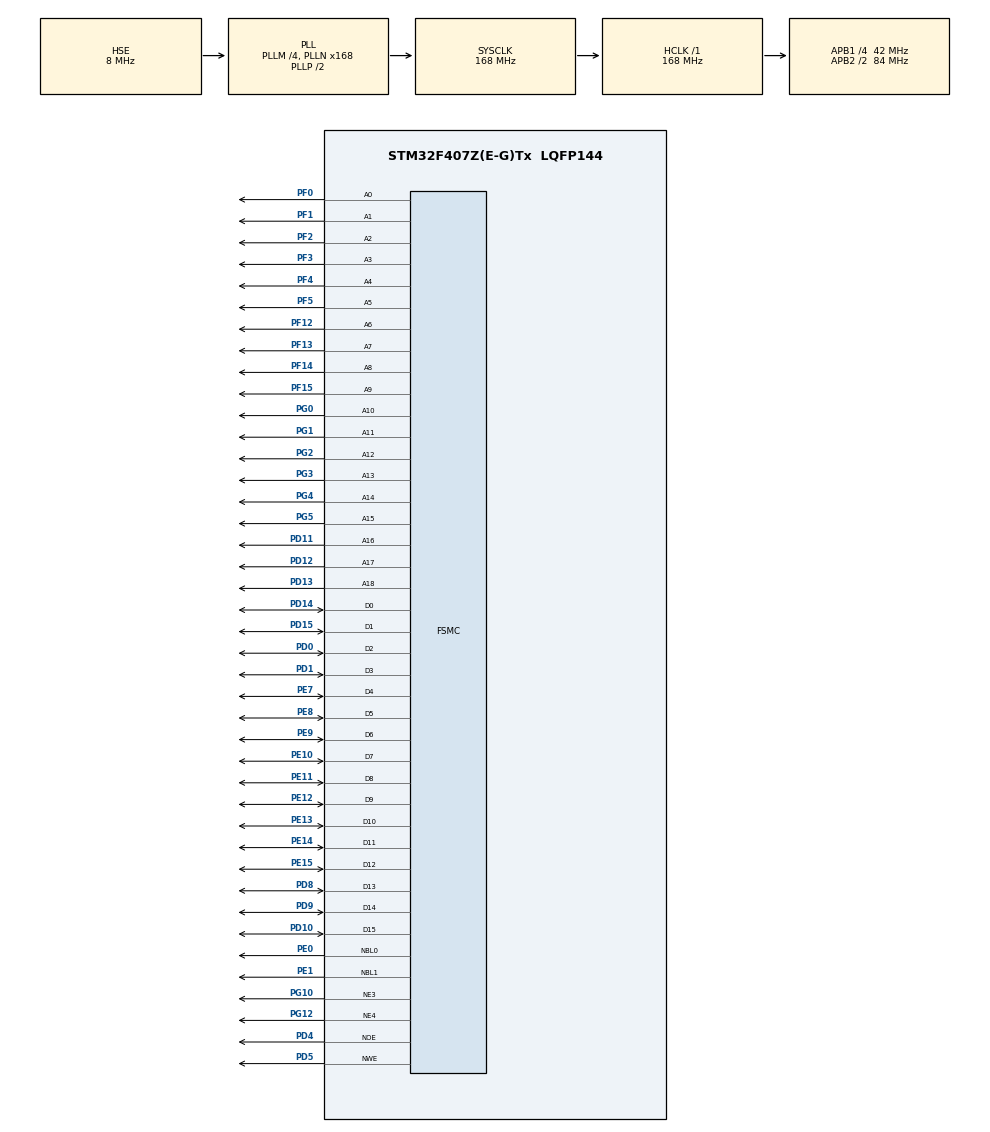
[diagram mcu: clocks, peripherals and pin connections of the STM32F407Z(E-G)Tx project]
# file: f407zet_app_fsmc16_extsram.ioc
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FSMC.AddressSetupTime1=3
FSMC.AddressSetupTime2=4
FSMC.BusTurnAroundDuration1=1
FSMC.BusTurnAroundDuration2=4
FSMC.DataSetupTime1=5
FSMC.DataSetupTime2=8
FSMC.WriteOperation1=FSMC_WRITE_OPERATION_ENABLE
Mcu.Family=STM32F4
Mcu.Name=STM32F407Z(E-G)Tx
Mcu.Package=LQFP144
NVIC.PriorityGroup=NVIC_PRIORITYGROUP_4
NVIC.TIM6_DAC_IRQn=true\:0\:0\:false\:false\:true\:false
NVIC.TimeBase=TIM6_DAC_IRQn
NVIC.TimeBaseIP=TIM6
PA13.Mode=Trace_Asynchronous_SW
PA13.Signal=SYS_JTMS-SWDIO
PA14.Mode=Trace_Asynchronous_SW
PA14.Signal=SYS_JTCK-SWCLK
PB3.Mode=Trace_Asynchronous_SW
PB3.Signal=SYS_JTDO-SWO
PC14-OSC32_IN.Mode=LSE-External-Oscillator
PC14-OSC32_IN.Signal=RCC_OSC32_IN
PC15-OSC32_OUT.Mode=LSE-External-Oscillator
PC15-OSC32_OUT.Signal=RCC_OSC32_OUT
PD0.Signal=FSMC_D2_DA2
PD1.Signal=FSMC_D3_DA3
PD10.Signal=FSMC_D15_DA15
PD11.Signal=FSMC_A16_CLE
PD12.Signal=FSMC_A17_ALE
PD13.Signal=FSMC_A18
PD14.Signal=FSMC_D0_DA0
PD15.Signal=FSMC_D1_DA1
PD4.Signal=FSMC_NOE
PD5.Signal=FSMC_NWE
PD8.Signal=FSMC_D13_DA13
PD9.Signal=FSMC_D14_DA14
PE0.Signal=FSMC_NBL0
PE1.Signal=FSMC_NBL1
PE10.Signal=FSMC_D7_DA7
PE11.Signal=FSMC_D8_DA8
PE12.Signal=FSMC_D9_DA9
PE13.Signal=FSMC_D10_DA10
PE14.Signal=FSMC_D11_DA11
PE15.Signal=FSMC_D12_DA12
PE7.Signal=FSMC_D4_DA4
PE8.Signal=FSMC_D5_DA5
PE9.Signal=FSMC_D6_DA6
PF0.Signal=FSMC_A0
PF1.Signal=FSMC_A1
PF12.Signal=FSMC_A6
PF13.Signal=FSMC_A7
PF14.Signal=FSMC_A8
PF15.Signal=FSMC_A9
PF2.Signal=FSMC_A2
PF3.Signal=FSMC_A3
PF4.Signal=FSMC_A4
PF5.Signal=FSMC_A5
PG0.Signal=FSMC_A10
PG1.Signal=FSMC_A11
PG10.Mode=NorPsramChipSelect3_1
PG10.Signal=FSMC_NE3
PG12.Mode=NorPsramChipSelect4_2
PG12.Signal=FSMC_NE4
PG2.Signal=FSMC_A12
PG3.Signal=FSMC_A13
PG4.Signal=FSMC_A14
PG5.Signal=FSMC_A15
PH0-OSC_IN.Mode=HSE-External-Oscillator
PH0-OSC_IN.Signal=RCC_OSC_IN
PH1-OSC_OUT.Mode=HSE-External-Oscillator
PH1-OSC_OUT.Signal=RCC_OSC_OUT
ProjectManager.HeapSize=0x200
ProjectManager.StackSize=0x800
ProjectManager.TargetToolchain=TrueSTUDIO
RCC.48MHZClocksFreq_Value=48000000
RCC.AHBFreq_Value=168000000
RCC.APB1CLKDivider=RCC_HCLK_DIV4
RCC.APB1Freq_Value=42000000
RCC.APB1TimFreq_Value=84000000
RCC.APB2CLKDivider=RCC_HCLK_DIV2
RCC.APB2Freq_Value=84000000
RCC.APB2TimFreq_Value=168000000
RCC.CortexFreq_Value=168000000
RCC.HCLKFreq_Value=168000000
RCC.HSE_VALUE=8000000
RCC.HSI_VALUE=16000000
RCC.PLLM=4
RCC.PLLN=168
RCC.PLLQ=7
RCC.PLLSourceVirtual=RCC_PLLSOURCE_HSE
RCC.RCC_RTC_Clock_Source=RCC_RTCCLKSOURCE_LSE
RCC.RCC_RTC_Clock_SourceVirtual=RCC_RTCCLKSOURCE_LSE
RCC.SYSCLKFreq_VALUE=168000000
RCC.SYSCLKSource=RCC_SYSCLKSOURCE_PLLCLK
RCC.VCOOutputFreq_Value=336000000
SH.FSMC_A0.0=FSMC_A0,19b-a1
SH.FSMC_A1.0=FSMC_A1,19b-a1
SH.FSMC_A10.0=FSMC_A10,19b-a1
SH.FSMC_A11.0=FSMC_A11,19b-a1
SH.FSMC_A12.0=FSMC_A12,19b-a1
SH.FSMC_A13.0=FSMC_A13,19b-a1
SH.FSMC_A14.0=FSMC_A14,19b-a1
SH.FSMC_A15.0=FSMC_A15,19b-a1
SH.FSMC_A16_CLE.0=FSMC_A16,19b-a1
SH.FSMC_A17_ALE.0=FSMC_A17,19b-a1
SH.FSMC_A18.0=FSMC_A18,19b-a1
SH.FSMC_A2.0=FSMC_A2,19b-a1
SH.FSMC_A3.0=FSMC_A3,19b-a1
SH.FSMC_A4.0=FSMC_A4,19b-a1
SH.FSMC_A5.0=FSMC_A5,19b-a1
SH.FSMC_A6.0=FSMC_A6,A6_2
SH.FSMC_A6.1=FSMC_A6,19b-a1
SH.FSMC_A7.0=FSMC_A7,19b-a1
SH.FSMC_A8.0=FSMC_A8,19b-a1
SH.FSMC_A9.0=FSMC_A9,19b-a1
SH.FSMC_D0_DA0.0=FSMC_D0,16b-d1
SH.FSMC_D0_DA0.1=FSMC_D0,16b-d2
SH.FSMC_D10_DA10.0=FSMC_D10,16b-d1
SH.FSMC_D10_DA10.1=FSMC_D10,16b-d2
SH.FSMC_D11_DA11.0=FSMC_D11,16b-d1
SH.FSMC_D11_DA11.1=FSMC_D11,16b-d2
SH.FSMC_D12_DA12.0=FSMC_D12,16b-d1
SH.FSMC_D12_DA12.1=FSMC_D12,16b-d2
SH.FSMC_D13_DA13.0=FSMC_D13,16b-d1
SH.FSMC_D13_DA13.1=FSMC_D13,16b-d2
SH.FSMC_D14_DA14.0=FSMC_D14,16b-d1
SH.FSMC_D14_DA14.1=FSMC_D14,16b-d2
SH.FSMC_D15_DA15.0=FSMC_D15,16b-d1
SH.FSMC_D15_DA15.1=FSMC_D15,16b-d2
SH.FSMC_D1_DA1.0=FSMC_D1,16b-d1
SH.FSMC_D1_DA1.1=FSMC_D1,16b-d2
SH.FSMC_D2_DA2.0=FSMC_D2,16b-d1
SH.FSMC_D2_DA2.1=FSMC_D2,16b-d2
SH.FSMC_D3_DA3.0=FSMC_D3,16b-d1
SH.FSMC_D3_DA3.1=FSMC_D3,16b-d2
SH.FSMC_D4_DA4.0=FSMC_D4,16b-d1
SH.FSMC_D4_DA4.1=FSMC_D4,16b-d2
SH.FSMC_D5_DA5.0=FSMC_D5,16b-d1
SH.FSMC_D5_DA5.1=FSMC_D5,16b-d2
SH.FSMC_D6_DA6.0=FSMC_D6,16b-d1
SH.FSMC_D6_DA6.1=FSMC_D6,16b-d2
SH.FSMC_D7_DA7.0=FSMC_D7,16b-d1
SH.FSMC_D7_DA7.1=FSMC_D7,16b-d2
SH.FSMC_D8_DA8.0=FSMC_D8,16b-d1
SH.FSMC_D8_DA8.1=FSMC_D8,16b-d2
SH.FSMC_D9_DA9.0=FSMC_D9,16b-d1
SH.FSMC_D9_DA9.1=FSMC_D9,16b-d2
SH.FSMC_NBL0.0=FSMC_NBL0,2ByteEnable1
SH.FSMC_NBL1.0=FSMC_NBL1,2ByteEnable1
SH.FSMC_NOE.0=FSMC_NOE,Lcd2
SH.FSMC_NOE.1=FSMC_NOE,Sram1
SH.FSMC_NWE.0=FSMC_NWE,Lcd2
SH.FSMC_NWE.1=FSMC_NWE,Sram1
VP_RTC_VS_RTC_Activate.Mode=RTC_Enabled
VP_SYS_VS_tim6.Mode=TIM6
board=custom

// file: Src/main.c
/**
  ******************************************************************************
  * @file           : main.c
  * @brief          : Main program body
  ******************************************************************************
  ** This notice applies to any and all portions of this file
  * that are not between comment pairs USER CODE BEGIN and
  * USER CODE END. Other portions of this file, whether
  * inserted by the user or by software development tools
  * are owned by their respective copyright owners.
  *
  * COPYRIGHT(c) 2019 STMicroelectronics
  *
  * Redistribution and use in source and binary forms, with or without modification,
  * are permitted provided that the following conditions are met:
  *   1. Redistributions of source code must retain the above copyright notice,
  *      this list of conditions and the following disclaimer.
  *   2. Redistributions in binary form must reproduce the above copyright notice,
  *      this list of conditions and the following disclaimer in the documentation
  *      and/or other materials provided with the distribution.
  *   3. Neither the name of STMicroelectronics nor the names of its contributors
  *      may be used to endorse or promote products derived from this software
  *      without specific prior written permission.
  *
  * THIS SOFTWARE IS PROVIDED BY THE COPYRIGHT HOLDERS AND CONTRIBUTORS "AS IS"
  * AND ANY EXPRESS OR IMPLIED WARRANTIES, INCLUDING, BUT NOT LIMITED TO, THE
  * IMPLIED WARRANTIES OF MERCHANTABILITY AND FITNESS FOR A PARTICULAR PURPOSE ARE
  * DISCLAIMED. IN NO EVENT SHALL THE COPYRIGHT HOLDER OR CONTRIBUTORS BE LIABLE
  * FOR ANY DIRECT, INDIRECT, INCIDENTAL, SPECIAL, EXEMPLARY, OR CONSEQUENTIAL
  * DAMAGES (INCLUDING, BUT NOT LIMITED TO, PROCUREMENT OF SUBSTITUTE GOODS OR
  * SERVICES; LOSS OF USE, DATA, OR PROFITS; OR BUSINESS INTERRUPTION) HOWEVER
  * CAUSED AND ON ANY THEORY OF LIABILITY, WHETHER IN CONTRACT, STRICT LIABILITY,
  * OR TORT (INCLUDING NEGLIGENCE OR OTHERWISE) ARISING IN ANY WAY OUT OF THE USE
  * OF THIS SOFTWARE, EVEN IF ADVISED OF THE POSSIBILITY OF SUCH DAMAGE.
  *
  ******************************************************************************
  */
#include "main.h"
#include "stm32f4xx_hal.h"

RTC_HandleTypeDef hrtc;

SRAM_HandleTypeDef hsram1;
SRAM_HandleTypeDef hsram2;

/* USER CODE BEGIN PV */
/* Private variables ---------------------------------------------------------*/

/* USER CODE END PV */

void SystemClock_Config(void);
static void MX_GPIO_Init(void);
static void MX_RTC_Init(void);
static void MX_FSMC_Init(void);

/* USER CODE BEGIN PFP */
/* Private function prototypes -----------------------------------------------*/
void mainApp(void);

/* USER CODE END PFP */

int main(void)
{

  /* MCU Configuration----------------------------------------------------------*/

  /* Reset of all peripherals, Initializes the Flash interface and the Systick. */
  HAL_Init();

  /* Configure the system clock */
  SystemClock_Config();

  /* Initialize all configured peripherals */
  MX_GPIO_Init();
  MX_RTC_Init();
  MX_FSMC_Init();

  /* Infinite loop */
  /* USER CODE BEGIN WHILE */
  mainApp();
  while (1)
  {

  /* USER CODE END WHILE */

  }

}

void SystemClock_Config(void)
{

  RCC_OscInitTypeDef RCC_OscInitStruct;
  RCC_ClkInitTypeDef RCC_ClkInitStruct;
  RCC_PeriphCLKInitTypeDef PeriphClkInitStruct;

    /**Configure the main internal regulator output voltage
    */
  __HAL_RCC_PWR_CLK_ENABLE();

  __HAL_PWR_VOLTAGESCALING_CONFIG(PWR_REGULATOR_VOLTAGE_SCALE1);

    /**Initializes the CPU, AHB and APB busses clocks
    */
  RCC_OscInitStruct.OscillatorType = RCC_OSCILLATORTYPE_HSE|RCC_OSCILLATORTYPE_LSE;
  RCC_OscInitStruct.HSEState = RCC_HSE_ON;
  RCC_OscInitStruct.LSEState = RCC_LSE_ON;
  RCC_OscInitStruct.PLL.PLLState = RCC_PLL_ON;
  RCC_OscInitStruct.PLL.PLLSource = RCC_PLLSOURCE_HSE;
  RCC_OscInitStruct.PLL.PLLM = 4;
  RCC_OscInitStruct.PLL.PLLN = 168;
  RCC_OscInitStruct.PLL.PLLP = RCC_PLLP_DIV2;
  RCC_OscInitStruct.PLL.PLLQ = 7;
  if (HAL_RCC_OscConfig(&RCC_OscInitStruct) != HAL_OK)
  {
    _Error_Handler(__FILE__, __LINE__);
  }

    /**Initializes the CPU, AHB and APB busses clocks
    */
  RCC_ClkInitStruct.ClockType = RCC_CLOCKTYPE_HCLK|RCC_CLOCKTYPE_SYSCLK
                              |RCC_CLOCKTYPE_PCLK1|RCC_CLOCKTYPE_PCLK2;
  RCC_ClkInitStruct.SYSCLKSource = RCC_SYSCLKSOURCE_PLLCLK;
  RCC_ClkInitStruct.AHBCLKDivider = RCC_SYSCLK_DIV1;
  RCC_ClkInitStruct.APB1CLKDivider = RCC_HCLK_DIV4;
  RCC_ClkInitStruct.APB2CLKDivider = RCC_HCLK_DIV2;

  if (HAL_RCC_ClockConfig(&RCC_ClkInitStruct, FLASH_LATENCY_5) != HAL_OK)
  {
    _Error_Handler(__FILE__, __LINE__);
  }

  PeriphClkInitStruct.PeriphClockSelection = RCC_PERIPHCLK_RTC;
  PeriphClkInitStruct.RTCClockSelection = RCC_RTCCLKSOURCE_LSE;
  if (HAL_RCCEx_PeriphCLKConfig(&PeriphClkInitStruct) != HAL_OK)
  {
    _Error_Handler(__FILE__, __LINE__);
  }

    /**Configure the Systick interrupt time
    */
  HAL_SYSTICK_Config(HAL_RCC_GetHCLKFreq()/1000);

    /**Configure the Systick
    */
  HAL_SYSTICK_CLKSourceConfig(SYSTICK_CLKSOURCE_HCLK);

  /* SysTick_IRQn interrupt configuration */
  HAL_NVIC_SetPriority(SysTick_IRQn, 0, 0);
}

/* RTC init function */
static void MX_RTC_Init(void)
{

    /**Initialize RTC Only
    */
  hrtc.Instance = RTC;
  hrtc.Init.HourFormat = RTC_HOURFORMAT_24;
  hrtc.Init.AsynchPrediv = 127;
  hrtc.Init.SynchPrediv = 255;
  hrtc.Init.OutPut = RTC_OUTPUT_DISABLE;
  hrtc.Init.OutPutPolarity = RTC_OUTPUT_POLARITY_HIGH;
  hrtc.Init.OutPutType = RTC_OUTPUT_TYPE_OPENDRAIN;
  if (HAL_RTC_Init(&hrtc) != HAL_OK)
  {
    _Error_Handler(__FILE__, __LINE__);
  }

}

/** Configure pins as
        * Analog
        * Input
        * Output
        * EVENT_OUT
        * EXTI
*/
static void MX_GPIO_Init(void)
{

  /* GPIO Ports Clock Enable */
  __HAL_RCC_GPIOC_CLK_ENABLE();
  __HAL_RCC_GPIOF_CLK_ENABLE();
  __HAL_RCC_GPIOH_CLK_ENABLE();
  __HAL_RCC_GPIOG_CLK_ENABLE();
  __HAL_RCC_GPIOE_CLK_ENABLE();
  __HAL_RCC_GPIOD_CLK_ENABLE();
  __HAL_RCC_GPIOA_CLK_ENABLE();
  __HAL_RCC_GPIOB_CLK_ENABLE();

}

/* FSMC initialization function */
static void MX_FSMC_Init(void)
{
  FSMC_NORSRAM_TimingTypeDef Timing;

  /** Perform the SRAM1 memory initialization sequence
  */
  hsram1.Instance = FSMC_NORSRAM_DEVICE;
  hsram1.Extended = FSMC_NORSRAM_EXTENDED_DEVICE;
  /* hsram1.Init */
  hsram1.Init.NSBank = FSMC_NORSRAM_BANK3;
  hsram1.Init.DataAddressMux = FSMC_DATA_ADDRESS_MUX_DISABLE;
  hsram1.Init.MemoryType = FSMC_MEMORY_TYPE_SRAM;
  hsram1.Init.MemoryDataWidth = FSMC_NORSRAM_MEM_BUS_WIDTH_16;
  hsram1.Init.BurstAccessMode = FSMC_BURST_ACCESS_MODE_DISABLE;
  hsram1.Init.WaitSignalPolarity = FSMC_WAIT_SIGNAL_POLARITY_LOW;
  hsram1.Init.WrapMode = FSMC_WRAP_MODE_DISABLE;
  hsram1.Init.WaitSignalActive = FSMC_WAIT_TIMING_BEFORE_WS;
  hsram1.Init.WriteOperation = FSMC_WRITE_OPERATION_ENABLE;
  hsram1.Init.WaitSignal = FSMC_WAIT_SIGNAL_DISABLE;
  hsram1.Init.ExtendedMode = FSMC_EXTENDED_MODE_DISABLE;
  hsram1.Init.AsynchronousWait = FSMC_ASYNCHRONOUS_WAIT_DISABLE;
  hsram1.Init.WriteBurst = FSMC_WRITE_BURST_DISABLE;
  hsram1.Init.PageSize = FSMC_PAGE_SIZE_NONE;
  /* Timing */
  Timing.AddressSetupTime = 3;
  Timing.AddressHoldTime = 15;
  Timing.DataSetupTime = 5;
  Timing.BusTurnAroundDuration = 1;
  Timing.CLKDivision = 16;
  Timing.DataLatency = 17;
  Timing.AccessMode = FSMC_ACCESS_MODE_A;
  /* ExtTiming */

  if (HAL_SRAM_Init(&hsram1, &Timing, NULL) != HAL_OK)
  {
    _Error_Handler(__FILE__, __LINE__);
  }

  /** Perform the SRAM2 memory initialization sequence
  */
  hsram2.Instance = FSMC_NORSRAM_DEVICE;
  hsram2.Extended = FSMC_NORSRAM_EXTENDED_DEVICE;
  /* hsram2.Init */
  hsram2.Init.NSBank = FSMC_NORSRAM_BANK4;
  hsram2.Init.DataAddressMux = FSMC_DATA_ADDRESS_MUX_DISABLE;
  hsram2.Init.MemoryType = FSMC_MEMORY_TYPE_SRAM;
  hsram2.Init.MemoryDataWidth = FSMC_NORSRAM_MEM_BUS_WIDTH_16;
  hsram2.Init.BurstAccessMode = FSMC_BURST_ACCESS_MODE_DISABLE;
  hsram2.Init.WaitSignalPolarity = FSMC_WAIT_SIGNAL_POLARITY_LOW;
  hsram2.Init.WrapMode = FSMC_WRAP_MODE_DISABLE;
  hsram2.Init.WaitSignalActive = FSMC_WAIT_TIMING_BEFORE_WS;
  hsram2.Init.WriteOperation = FSMC_WRITE_OPERATION_ENABLE;
  hsram2.Init.WaitSignal = FSMC_WAIT_SIGNAL_DISABLE;
  hsram2.Init.ExtendedMode = FSMC_EXTENDED_MODE_DISABLE;
  hsram2.Init.AsynchronousWait = FSMC_ASYNCHRONOUS_WAIT_DISABLE;
  hsram2.Init.WriteBurst = FSMC_WRITE_BURST_DISABLE;
  hsram2.Init.PageSize = FSMC_PAGE_SIZE_NONE;
  /* Timing */
  Timing.AddressSetupTime = 4;
  Timing.AddressHoldTime = 15;
  Timing.DataSetupTime = 8;
  Timing.BusTurnAroundDuration = 4;
  Timing.CLKDivision = 16;
  Timing.DataLatency = 17;
  Timing.AccessMode = FSMC_ACCESS_MODE_A;
  /* ExtTiming */

  if (HAL_SRAM_Init(&hsram2, &Timing, NULL) != HAL_OK)
  {
    _Error_Handler(__FILE__, __LINE__);
  }

}

void HAL_TIM_PeriodElapsedCallback(TIM_HandleTypeDef *htim)
{
  if (htim->Instance == TIM6) {
    HAL_IncTick();
  }
}

void _Error_Handler(char *file, int line)
{
  while(1)
  {
  }
}

/************************ (C) COPYRIGHT STMicroelectronics *****END OF FILE****/
